# STM32F446 register map
File version: 1.1
CPU: CM4 r1p0, little endian, no MPU, no FPU, 4 interrupt priority bits
Registers are 32-bit, read-write, reset 0x0 unless marked. A register's access mark holds for its fields unless they carry their own. Offsets are from the block's base; [hi:lo] are bit positions; {n}, {i} and the like mark numbered series; 'fields as' and 'values as' point back to an identical list.

## OTG_HS_GLOBAL — USB on the go high speed
Base 0x40040000
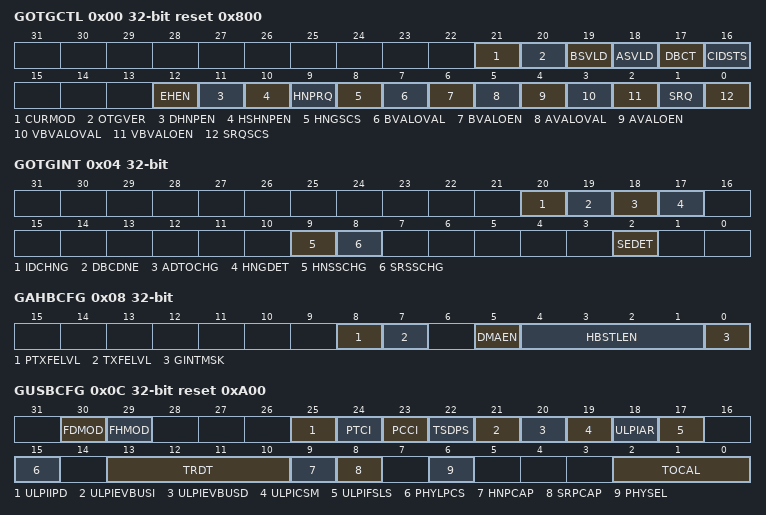
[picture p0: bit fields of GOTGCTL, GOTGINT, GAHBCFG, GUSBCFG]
0x00 GOTGCTL access per field reset 0x800 — OTG control and status register
  [21] CURMOD ro
  [20] OTGVER rw — OTG version
  [19] BSVLD ro — B-session valid
  [18] ASVLD ro — A-session valid
  [17] DBCT ro — Long/short debounce time
  [16] CIDSTS ro — Connector ID status
  [12] EHEN rw — Embedded host enable
  [11] DHNPEN rw — Device HNP enabled
  [10] HSHNPEN rw — Host set HNP enable
  [9] HNPRQ rw — HNP request
  [8] HNGSCS ro — Host negotiation success
  [7] BVALOVAL rw — B-peripheral session valid override value
  [6] BVALOEN rw — B-peripheral session valid override enable
  [5] AVALOVAL rw — A-peripheral session valid override value
  [4] AVALOEN rw — A-peripheral session valid override enable
  [3] VBVALOVAL rw — VBUS valid override value
  [2] VBVALOEN rw — VBUS valid override enable
  [1] SRQ rw — Session request
  [0] SRQSCS ro — Session request success
0x04 GOTGINT — OTG interrupt register
  [20] IDCHNG — ID pin value changed
  [19] DBCDNE — Debounce done
  [18] ADTOCHG — A-device timeout change
  [17] HNGDET — Host negotiation detected
  [9] HNSSCHG — Host negotiation success status change
  [8] SRSSCHG — Session request success status change
  [2] SEDET — Session end detected
0x08 GAHBCFG — OTG AHB configuration register
  [8] PTXFELVL — Periodic Tx FIFO empty level
  [7] TXFELVL — Tx FIFO empty level
  [5] DMAEN — DMA enable
  [4:1] HBSTLEN — Burst length/type
  [0] GINTMSK — Global interrupt mask
0x0C GUSBCFG access per field reset 0xA00 — OTG USB configuration register
  [30] FDMOD rw — Force device mode
  [29] FHMOD rw — Force host mode
  [25] ULPIIPD rw — ULPI interface protect disable
  [24] PTCI rw — Indicator pass through
  [23] PCCI rw — Indicator complement
  [22] TSDPS rw — TermSel DLine pulsing selection
  [21] ULPIEVBUSI rw — ULPI external VBUS indicator
  [20] ULPIEVBUSD rw — ULPI External VBUS Drive
  [19] ULPICSM rw — ULPI Clock SuspendM
  [18] ULPIAR rw — ULPI Auto-resume
  [17] ULPIFSLS rw — ULPI FS/LS select
  [15] PHYLPCS rw — PHY Low-power clock select
  [13:10] TRDT rw — USB turnaround time
  [9] HNPCAP rw — HNP-capable
  [8] SRPCAP rw — SRP-capable
  [6] PHYSEL wo — Full Speed serial transceiver select
  [2:0] TOCAL rw — FS timeout calibration
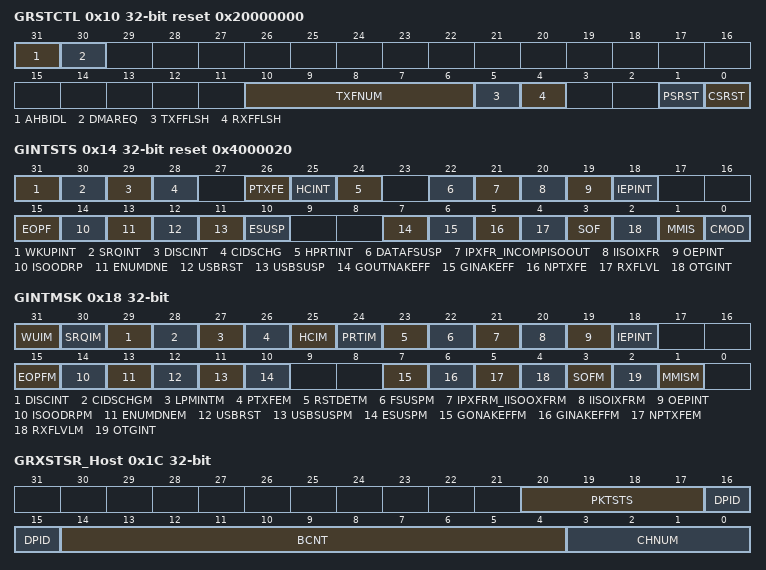
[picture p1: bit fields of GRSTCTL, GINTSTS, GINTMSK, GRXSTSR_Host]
0x10 GRSTCTL access per field reset 0x20000000 — OTG reset register
  [31] AHBIDL ro — AHB master idle
  [30] DMAREQ ro — DMA request signal
  [10:6] TXFNUM rw — Tx FIFO number
  [5] TXFFLSH rw — Tx FIFO flush
  [4] RXFFLSH rw — Rx FIFO flush
  [1] PSRST rw — Partial soft reset
  [0] CSRST rw — Core soft reset
0x14 GINTSTS access per field reset 0x4000020 — OTG core interrupt register
  [31] WKUPINT rw — Resume/remote wakeup detected interrupt
  [30] SRQINT rw — Session request/new session detected interrupt
  [29] DISCINT rw — Disconnect detected interrupt
  [28] CIDSCHG rw — Connector ID status change
  [26] PTXFE ro — Periodic TxFIFO empty
  [25] HCINT ro — Host channels interrupt
  [24] HPRTINT ro — Host port interrupt
  [22] DATAFSUSP rw — Data fetch suspended
  [21] IPXFR_INCOMPISOOUT rw — Incomplete periodic transfer (Host mode)/Incomplete isochronous OUT transfer (Device mode)
  [20] IISOIXFR rw — Incomplete isochronous IN transfer
  [19] OEPINT ro — OUT endpoint interrupt
  [18] IEPINT ro — IN endpoint interrupt
  [15] EOPF rw — End of periodic frame interrupt
  [14] ISOODRP rw — Isochronous OUT packet dropped interrupt
  [13] ENUMDNE rw — Enumeration done
  [12] USBRST rw — USB reset
  [11] USBSUSP rw — USB suspend
  [10] ESUSP rw — Early suspend
  [7] GOUTNAKEFF ro — Global OUT NAK effective
  [6] GINAKEFF ro — Global IN non-periodic NAK effective
  [5] NPTXFE ro — Non-periodic Tx FIFO empty
  [4] RXFLVL ro — Rx FIFO non-empty
  [3] SOF rw — Start of frame
  [2] OTGINT ro — OTG interrupt
  [1] MMIS rw — Mode mismatch interrupt
  [0] CMOD ro — Current mode of operation
0x18 GINTMSK access per field — OTG interrupt mask register
  [31] WUIM rw — Resume/remote wakeup detected interrupt mask
  [30] SRQIM rw — Session request/new session detected interrupt mask
  [29] DISCINT rw — Disconnect detected interrupt mask
  [28] CIDSCHGM rw — Connector ID status change mask
  [27] LPMINTM rw — LPM interrupt mask
  [26] PTXFEM rw — Periodic Tx FIFO empty mask
  [25] HCIM rw — Host channels interrupt mask
  [24] PRTIM ro — Host port interrupt mask
  [23] RSTDETM rw — Reset detected interrupt mask
  [22] FSUSPM rw — Data fetch suspended mask
  [21] IPXFRM_IISOOXFRM rw — Incomplete periodic transfer mask (Host mode)/Incomplete isochronous OUT transfer mask (Device mode)
  [20] IISOIXFRM rw — Incomplete isochronous IN transfer mask
  [19] OEPINT rw — OUT endpoints interrupt mask
  [18] IEPINT rw — IN endpoints interrupt mask
  [15] EOPFM rw — End of periodic frame interrupt mask
  [14] ISOODRPM rw — Isochronous OUT packet dropped interrupt mask
  [13] ENUMDNEM rw — Enumeration done mask
  [12] USBRST rw — USB reset mask
  [11] USBSUSPM rw — USB suspend mask
  [10] ESUSPM rw — Early suspend mask
  [7] GONAKEFFM rw — Global OUT NAK effective mask
  [6] GINAKEFFM rw — Global non-periodic IN NAK effective mask
  [5] NPTXFEM rw — Non-periodic Tx FIFO empty mask
  [4] RXFLVLM rw — Receive FIFO non-empty mask
  [3] SOFM rw — Start of frame mask
  [2] OTGINT rw — OTG interrupt mask
  [1] MMISM rw — Mode mismatch interrupt mask
0x1C GRXSTSR_Host ro — OTG receive status debug read register (Host mode)
  [20:17] PKTSTS — Packet status
  [16:15] DPID — Data PID
  [14:4] BCNT — Byte count
  [3:0] CHNUM — Channel number
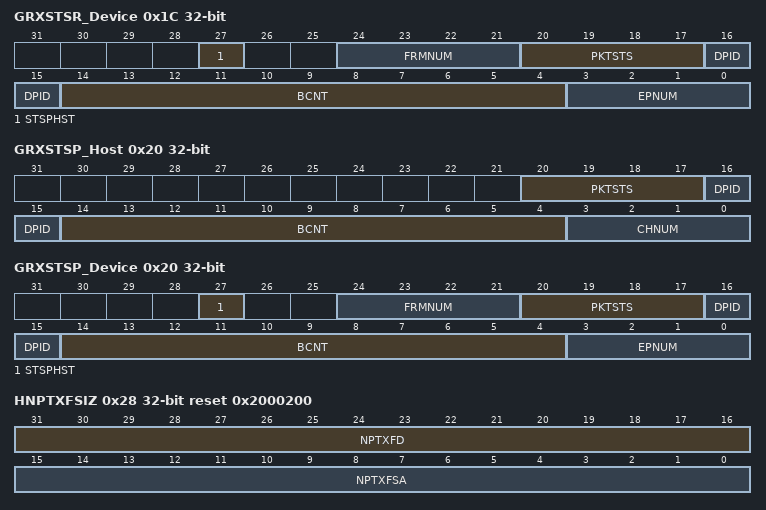
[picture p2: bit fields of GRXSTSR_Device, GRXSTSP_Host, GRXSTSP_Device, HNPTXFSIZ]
0x1C GRXSTSR_Device ro (alternate view of GRXSTSR_Host) — OTG receive status debug read register (Device mode)
  [27] STSPHST — Status phase start
  [24:21] FRMNUM — Frame number
  [20:17] PKTSTS — Packet status
  [16:15] DPID — Data PID
  [14:4] BCNT — Byte count
  [3:0] EPNUM — Endpoint number
0x20 GRXSTSP_Host ro — OTG status read and pop register (Host mode)
  fields as GRXSTSR_Host
0x20 GRXSTSP_Device ro (alternate view of GRXSTSP_Host) — OTG status read and pop register (Device mode)
  fields as GRXSTSR_Device
0x24 GRXFSIZ reset 0x400 — OTG Receive FIFO size register
  [15:0] RXFD — RxFIFO depth
0x28 HNPTXFSIZ reset 0x2000200 — OTG non-periodic transmit FIFO size register (Host mode)
  [31:16] NPTXFD — Non-periodic TxFIFO depth
  [15:0] NPTXFSA — Non-periodic transmit RAM start address
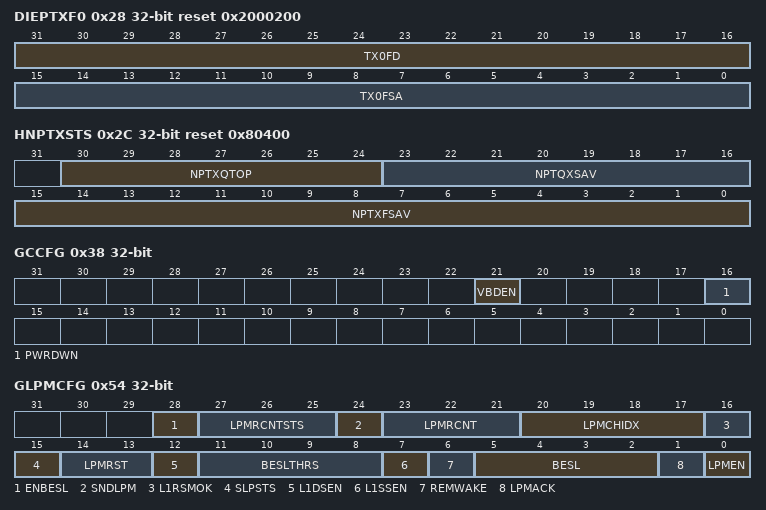
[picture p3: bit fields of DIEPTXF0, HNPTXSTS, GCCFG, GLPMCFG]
0x28 DIEPTXF0 reset 0x2000200 (alternate view of HNPTXFSIZ) — Endpoint 0 transmit FIFO size (Device mode)
  [31:16] TX0FD — Endpoint 0 Tx FIFO depth
  [15:0] TX0FSA — Endpoint 0 transmit RAM start address
0x2C HNPTXSTS ro reset 0x80400 — OTG non-periodic transmit FIFO/queue status register
  [30:24] NPTXQTOP — Top of the non-periodic transmit request queue
  [23:16] NPTQXSAV — Non-periodic transmit request queue space available
  [15:0] NPTXFSAV — Non-periodic Tx FIFO space available
0x38 GCCFG — OTG general core configuration register
  [21] VBDEN — USB VBUS detection enable
  [16] PWRDWN — Power down
0x3C CID reset 0x2100 — OTG core ID register
  [31:0] PRODUCT_ID
0x54 GLPMCFG access per field — OTG core LPM configuration register
  [28] ENBESL rw — Enable best effort service latency
  [27:25] LPMRCNTSTS ro — LPM retry count status
  [24] SNDLPM rw — Send LPM transaction
  [23:21] LPMRCNT rw — LPM retry count
  [20:17] LPMCHIDX rw — LPM Channel Index
  [16] L1RSMOK ro — Sleep State Resume OK
  [15] SLPSTS ro — Port sleep status
  [14:13] LPMRST ro — LPM response
  [12] L1DSEN rw — L1 deep sleep enable
  [11:8] BESLTHRS rw — BESL threshold
  [7] L1SSEN rw — L1 Shallow Sleep enable
  [6] REMWAKE ro — bRemoteWake value
  [5:2] BESL ro — Best effort service latency
  [1] LPMACK rw — LPM token acknowledge enable
  [0] LPMEN rw — LPM support enable
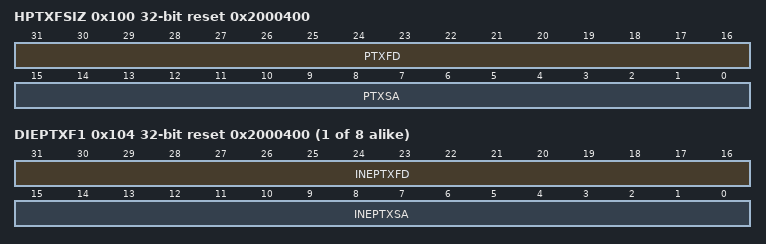
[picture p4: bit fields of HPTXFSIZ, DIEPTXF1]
0x100 HPTXFSIZ reset 0x2000400 — OTG Host periodic transmit FIFO size register
  [31:16] PTXFD — Host periodic Tx FIFO depth
  [15:0] PTXSA — Host periodic Tx FIFO start address
{0x100+4i} DIEPTXF{i} (i=1..8) reset 0x2000400 — OTG device IN endpoint transmit FIFO size register
  [31:16] INEPTXFD — IN endpoint Tx FIFO depth
  [15:0] INEPTXSA — IN endpoint FIFOx transmit RAM start address

## OTG_HS_PWRCLK — USB on the go high speed
Base 0x40040E00
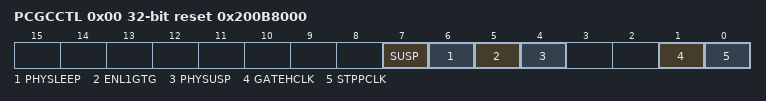
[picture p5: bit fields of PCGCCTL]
0x00 PCGCCTL access per field reset 0x200B8000 — OTG power and clock gating control register
  [7] SUSP ro — Deep Sleep
  [6] PHYSLEEP ro — PHY in Sleep
  [5] ENL1GTG rw — Enable sleep clock gating
  [4] PHYSUSP ro — PHY suspended
  [1] GATEHCLK rw
  [0] STPPCLK rw — Stop PHY clock
